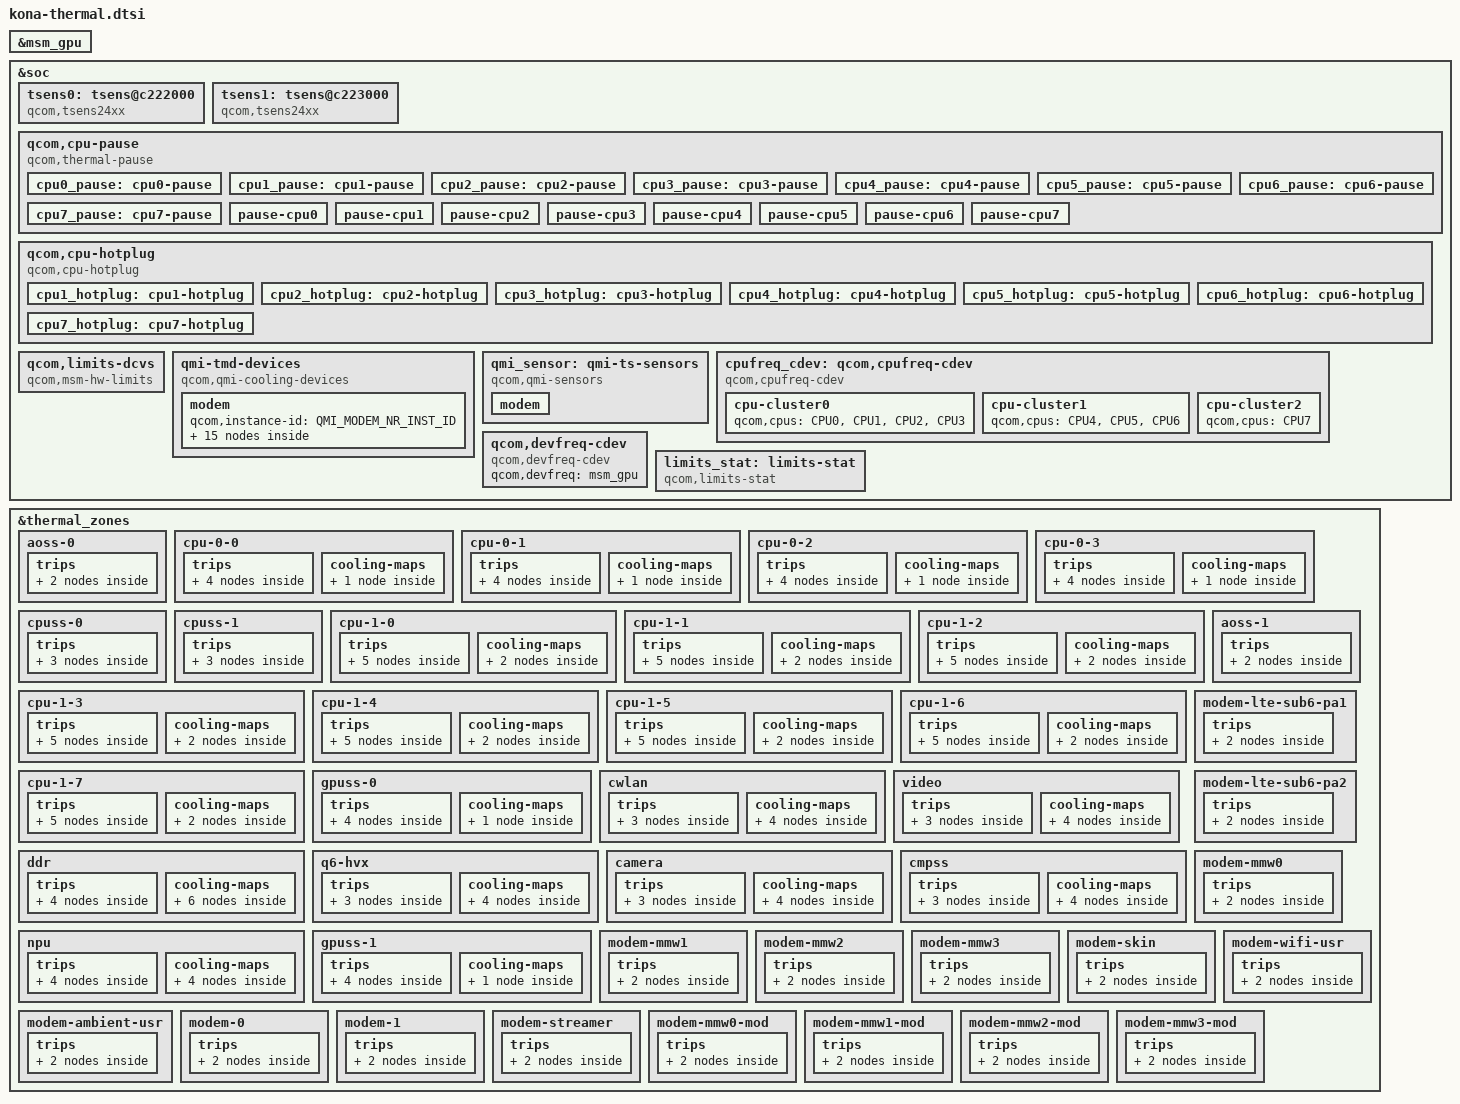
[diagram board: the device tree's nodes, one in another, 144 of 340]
#include <dt-bindings/thermal/thermal_qti.h>

&msm_gpu {
	#cooling-cells = <2>;
};

&soc {
	tsens0: tsens@c222000 {
		compatible = "qcom,tsens24xx";
		reg = <0xc222000 0x8>,
			<0xc263000 0x1ff>;
		reg-names = "tsens_srot_physical",
				"tsens_tm_physical";
		interrupts = <GIC_SPI 506 IRQ_TYPE_LEVEL_HIGH>,
				<GIC_SPI 508 IRQ_TYPE_LEVEL_HIGH>;
		interrupt-names = "tsens-upper-lower", "tsens-critical";
		tsens-reinit-wa;
		#thermal-sensor-cells = <1>;
	};

	tsens1: tsens@c223000 {
		compatible = "qcom,tsens24xx";
		reg = <0xc223000 0x8>,
			<0xc265000 0x1ff>;
		reg-names = "tsens_srot_physical",
			"tsens_tm_physical";
		interrupts = <GIC_SPI 507 IRQ_TYPE_LEVEL_HIGH>,
				<GIC_SPI 509 IRQ_TYPE_LEVEL_HIGH>;
		interrupt-names = "tsens-upper-lower", "tsens-critical";
		tsens-reinit-wa;
		#thermal-sensor-cells = <1>;
	};

	qcom,cpu-pause {
		compatible = "qcom,thermal-pause";

		cpu0_pause: cpu0-pause {
			qcom,cpus = <&CPU0>;
			qcom,cdev-alias = "thermal-pause-1";
			#cooling-cells = <2>;
		};

		cpu1_pause: cpu1-pause {
			qcom,cpus = <&CPU1>;
			qcom,cdev-alias = "thermal-pause-2";
			#cooling-cells = <2>;
		};

		cpu2_pause: cpu2-pause {
			qcom,cpus = <&CPU2>;
			qcom,cdev-alias = "thermal-pause-4";
			#cooling-cells = <2>;
		};

		cpu3_pause: cpu3-pause {
			qcom,cpus = <&CPU3>;
			qcom,cdev-alias = "thermal-pause-8";
			#cooling-cells = <2>;
		};

		cpu4_pause: cpu4-pause {
			qcom,cpus = <&CPU4>;
			qcom,cdev-alias = "thermal-pause-10";
			#cooling-cells = <2>;
		};

		cpu5_pause: cpu5-pause {
			qcom,cpus = <&CPU5>;
			qcom,cdev-alias = "thermal-pause-20";
			#cooling-cells = <2>;
		};

		cpu6_pause: cpu6-pause {
			qcom,cpus = <&CPU6>;
			qcom,cdev-alias = "thermal-pause-40";
			#cooling-cells = <2>;
		};

		cpu7_pause: cpu7-pause {
			qcom,cpus = <&CPU7>;
			qcom,cdev-alias = "thermal-pause-80";
			#cooling-cells = <2>;
		};

		/* Thermal-engine cooling devices */

		pause-cpu0 {
			qcom,cpus = <&CPU0>;
			qcom,cdev-alias = "pause-cpu0";
		};

		pause-cpu1 {
			qcom,cpus = <&CPU1>;
			qcom,cdev-alias = "pause-cpu1";
		};

		pause-cpu2 {
			qcom,cpus = <&CPU2>;
			qcom,cdev-alias = "pause-cpu2";
		};

		pause-cpu3 {
			qcom,cpus = <&CPU3>;
			qcom,cdev-alias = "pause-cpu3";
		};

		pause-cpu4 {
			qcom,cpus = <&CPU4>;
			qcom,cdev-alias = "pause-cpu4";
		};

		pause-cpu5 {
			qcom,cpus = <&CPU5>;
			qcom,cdev-alias = "pause-cpu5";
		};

		pause-cpu6 {
			qcom,cpus = <&CPU6>;
			qcom,cdev-alias = "pause-cpu6";
		};

		pause-cpu7 {
			qcom,cpus = <&CPU7>;
			qcom,cdev-alias = "pause-cpu7";
		};
	};

	qcom,cpu-hotplug {
		compatible = "qcom,cpu-hotplug";

		cpu1_hotplug: cpu1-hotplug {
			qcom,cpu = <&CPU1>;
			qcom,cdev-alias = "cpu-hotplug1";
			#cooling-cells = <2>;
		};

		cpu2_hotplug: cpu2-hotplug {
			qcom,cpu = <&CPU2>;
			qcom,cdev-alias = "cpu-hotplug2";
			#cooling-cells = <2>;
		};

		cpu3_hotplug: cpu3-hotplug {
			qcom,cpu = <&CPU3>;
			qcom,cdev-alias = "cpu-hotplug3";
			#cooling-cells = <2>;
		};

		cpu4_hotplug: cpu4-hotplug {
			qcom,cpu = <&CPU4>;
			qcom,cdev-alias = "cpu-hotplug4";
			#cooling-cells = <2>;
		};

		cpu5_hotplug: cpu5-hotplug {
			qcom,cpu = <&CPU5>;
			qcom,cdev-alias = "cpu-hotplug5";
			#cooling-cells = <2>;
		};

		cpu6_hotplug: cpu6-hotplug {
			qcom,cpu = <&CPU6>;
			qcom,cdev-alias = "cpu-hotplug6";
			#cooling-cells = <2>;
		};

		cpu7_hotplug: cpu7-hotplug {
			qcom,cpu = <&CPU7>;
			qcom,cdev-alias = "cpu-hotplug7";
			#cooling-cells = <2>;
		};
	};

	qcom,limits-dcvs {
		compatible = "qcom,msm-hw-limits";
		isens_vref_0p8-supply = <&pm8150_l5_ao>;
		isens-vref-0p8-settings = <880000 880000 20000>;
		isens_vref_1p8-supply = <&pm8150_l12_ao>;
		isens-vref-1p8-settings = <1800000 1800000 20000>;
	};

	qmi-tmd-devices {
		compatible = "qcom,qmi-cooling-devices";

		modem {
			qcom,instance-id = <QMI_MODEM_NR_INST_ID>;

			modem_pa: modem_pa {
				qcom,qmi-dev-name = "pa";
				#cooling-cells = <2>;
			};

			modem_pa_fr1: modem_pa_fr1 {
				qcom,qmi-dev-name = "pa_fr1";
				#cooling-cells = <2>;
			};

			modem_tj: modem_tj {
				qcom,qmi-dev-name = "modem";
				#cooling-cells = <2>;
			};

			modem_current: modem_current {
				qcom,qmi-dev-name = "modem_current";
				#cooling-cells = <2>;
			};

			modem_skin: modem_skin {
				qcom,qmi-dev-name = "modem_skin";
				#cooling-cells = <2>;
			};

			modem_mmw_skin0: modem_mmw_skin0 {
				qcom,qmi-dev-name = "mmw_skin0";
				#cooling-cells = <2>;
			};

			modem_mmw_skin1: modem_mmw_skin1 {
				qcom,qmi-dev-name = "mmw_skin1";
				#cooling-cells = <2>;
			};

			modem_mmw_skin2: modem_mmw_skin2 {
				qcom,qmi-dev-name = "mmw_skin2";
				#cooling-cells = <2>;
			};

			modem_mmw_skin3: modem_mmw_skin3 {
				qcom,qmi-dev-name = "mmw_skin3";
				#cooling-cells = <2>;
			};

			modem_mmw0: modem_mmw0 {
				qcom,qmi-dev-name = "mmw0";
				#cooling-cells = <2>;
			};

			modem_mmw1: modem_mmw1 {
				qcom,qmi-dev-name = "mmw1";
				#cooling-cells = <2>;
			};

			modem_mmw2: modem_mmw2 {
				qcom,qmi-dev-name = "mmw2";
				#cooling-cells = <2>;
			};

			modem_mmw3: modem_mmw3 {
				qcom,qmi-dev-name = "mmw3";
				#cooling-cells = <2>;
			};

			modem_bcl: modem_bcl {
				qcom,qmi-dev-name = "vbatt_low";
				#cooling-cells = <2>;
			};

			modem_charge_state: modem_charge_state {
				qcom,qmi-dev-name = "charge_state";
				#cooling-cells = <2>;
			};
		};
	};

	qmi_sensor: qmi-ts-sensors {
		compatible = "qcom,qmi-sensors";
		#thermal-sensor-cells = <1>;

		modem {
			qcom,instance-id = <QMI_MODEM_NR_INST_ID>;
			qcom,qmi-sensor-names = "pa",
						"pa_1",
						"qfe_wtr0",
						"modem_tsens",
						"qfe_mmw0",
						"qfe_mmw1",
						"qfe_mmw2",
						"qfe_mmw3",
						"xo_therm",
						"qfe_mmw_streamer0",
						"qfe_mmw0_mod",
						"qfe_mmw1_mod",
						"qfe_mmw2_mod",
						"qfe_mmw3_mod",
						"qfe_ret_pa0",
						"qfe_wtr_pa0",
						"qfe_wtr_pa1",
						"qfe_wtr_pa2",
						"qfe_wtr_pa3",
						"sys_therm1",
						"sys_therm2",
						"modem_tsens1";
		};
	};

	cpufreq_cdev: qcom,cpufreq-cdev {
		compatible = "qcom,cpufreq-cdev";
		cpu-cluster0 {
			qcom,cpus = <&CPU0 &CPU1 &CPU2 &CPU3>;
		};

		cpu-cluster1 {
			qcom,cpus = <&CPU4 &CPU5 &CPU6>;
		};

		cpu-cluster2 {
			qcom,cpus = <&CPU7>;
		};
	};

	qcom,devfreq-cdev {
		compatible = "qcom,devfreq-cdev";
		qcom,devfreq = <&msm_gpu>;
	};

	limits_stat: limits-stat {
		compatible = "qcom,limits-stat";
		qcom,limits-stat-sensor-names = "cpu-0-0",
						"cpu-0-1",
						"cpu-0-2",
						"cpu-0-3",
						"cpu-1-0",
						"cpu-1-1",
						"cpu-1-2",
						"cpu-1-3",
						"cpuss-0",
						"gpuss-0",
						"gpuss-1",
						"npu",
						"q6-hvx";
	};
};

&thermal_zones {
	aoss-0 {
		polling-delay-passive = <0>;
		polling-delay = <0>;
		thermal-sensors = <&tsens0 0>;
		trips {
			thermal-engine-config {
				temperature = <125000>;
				hysteresis = <1000>;
				type = "passive";
			};

			reset-mon-cfg {
				temperature = <115000>;
				hysteresis = <1000>;
				type = "passive";
			};
		};
	};

	cpu-0-0 {
		polling-delay-passive = <0>;
		polling-delay = <0>;
		thermal-sensors = <&tsens0 1>;
		trips {
			thermal-engine-config {
				temperature = <125000>;
				hysteresis = <1000>;
				type = "passive";
			};

			thermal-hal-config {
				temperature = <125000>;
				hysteresis = <1000>;
				type = "passive";
			};

			cpu00_config: cpu00-config {
				temperature = <110000>;
				hysteresis = <10000>;
				type = "passive";
			};

			reset-mon-cfg {
				temperature = <115000>;
				hysteresis = <1000>;
				type = "passive";
			};
		};

		cooling-maps {
			cpu00_cdev {
				trip = <&cpu00_config>;
				cooling-device = <&cpu0_pause 1 1>;
			};
		};
	};

	cpu-0-1 {
		polling-delay-passive = <0>;
		polling-delay = <0>;
		thermal-sensors = <&tsens0 2>;
		trips {
			thermal-engine-config {
				temperature = <125000>;
				hysteresis = <1000>;
				type = "passive";
			};

			thermal-hal-config {
				temperature = <125000>;
				hysteresis = <1000>;
				type = "passive";
			};

			cpu01_config: cpu01-config {
				temperature = <110000>;
				hysteresis = <10000>;
				type = "passive";
			};

			reset-mon-cfg {
				temperature = <115000>;
				hysteresis = <1000>;
				type = "passive";
			};
		};

		cooling-maps {
			cpu01_cdev {
				trip = <&cpu01_config>;
				cooling-device = <&cpu1_pause 1 1>;
			};
		};
	};

	cpu-0-2 {
		polling-delay-passive = <0>;
		polling-delay = <0>;
		thermal-sensors = <&tsens0 3>;
		trips {
			thermal-engine-config {
				temperature = <125000>;
				hysteresis = <1000>;
				type = "passive";
			};

			thermal-hal-config {
				temperature = <125000>;
				hysteresis = <1000>;
				type = "passive";
			};

			cpu02_config: cpu02-config {
				temperature = <110000>;
				hysteresis = <10000>;
				type = "passive";
			};

			reset-mon-cfg {
				temperature = <115000>;
				hysteresis = <1000>;
				type = "passive";
			};
		};

		cooling-maps {
			cpu02_cdev {
				trip = <&cpu02_config>;
				cooling-device = <&cpu2_pause 1 1>;
			};
		};
	};

	cpu-0-3 {
		polling-delay-passive = <0>;
		polling-delay = <0>;
		thermal-sensors = <&tsens0 4>;
		trips {
			thermal-engine-config {
				temperature = <125000>;
				hysteresis = <1000>;
				type = "passive";
			};

			thermal-hal-config {
				temperature = <125000>;
				hysteresis = <1000>;
				type = "passive";
			};

			cpu03_config: cpu03-config {
				temperature = <110000>;
				hysteresis = <10000>;
				type = "passive";
			};

			reset-mon-cfg {
				temperature = <115000>;
				hysteresis = <1000>;
				type = "passive";
			};
		};

		cooling-maps {
			cpu03_cdev {
				trip = <&cpu03_config>;
				cooling-device = <&cpu3_pause 1 1>;
			};
		};
	};

	cpuss-0 {
		polling-delay-passive = <0>;
		polling-delay = <0>;
		thermal-sensors = <&tsens0 5>;
		trips {
			thermal-engine-config {
				temperature = <125000>;
				hysteresis = <1000>;
				type = "passive";
			};

			thermal-hal-config {
				temperature = <125000>;
				hysteresis = <1000>;
				type = "passive";
			};

			reset-mon-cfg {
				temperature = <115000>;
				hysteresis = <1000>;
				type = "passive";
			};
		};
	};

	cpuss-1 {
		polling-delay-passive = <0>;
		polling-delay = <0>;
		thermal-sensors = <&tsens0 6>;
		trips {
			thermal-engine-config {
				temperature = <125000>;
				hysteresis = <1000>;
				type = "passive";
			};

			thermal-hal-config {
				temperature = <125000>;
				hysteresis = <1000>;
				type = "passive";
			};

			reset-mon-cfg {
				temperature = <115000>;
				hysteresis = <1000>;
				type = "passive";
			};
		};
	};

	cpu-1-0 {
		polling-delay-passive = <10>;
		polling-delay = <0>;
		thermal-sensors = <&tsens0 7>;
		trips {
			thermal-engine-config {
				temperature = <125000>;
				hysteresis = <1000>;
				type = "passive";
			};

			thermal-hal-config {
				temperature = <125000>;
				hysteresis = <1000>;
				type = "passive";
			};

			cpufreq_10_config: cpufreq-10-config {
				temperature = <75000>;
				hysteresis = <5000>;
				type = "passive";
			};

			cpu10_config: cpu10-config {
				temperature = <110000>;
				hysteresis = <10000>;
				type = "passive";
			};

			reset-mon-cfg {
				temperature = <115000>;
				hysteresis = <1000>;
				type = "passive";
			};
		};

		cooling-maps {
			cpufreq_cdev {
				trip = <&cpufreq_10_config>;
				cooling-device = <&cpu7_notify 1 1>;
			};

			cpu10_cdev {
				trip = <&cpu10_config>;
				cooling-device = <&cpu4_pause 1 1>;
			};
		};
	};

	cpu-1-1 {
		polling-delay-passive = <10>;
		polling-delay = <0>;
		thermal-sensors = <&tsens0 8>;
		trips {
			thermal-engine-config {
				temperature = <125000>;
				hysteresis = <1000>;
				type = "passive";
			};

			thermal-hal-config {
				temperature = <125000>;
				hysteresis = <1000>;
				type = "passive";
			};

			cpufreq_11_config: cpufreq-11-config {
				temperature = <75000>;
				hysteresis = <5000>;
				type = "passive";
			};

			cpu11_config: cpu11-config {
				temperature = <110000>;
				hysteresis = <10000>;
				type = "passive";
			};

			reset-mon-cfg {
				temperature = <115000>;
				hysteresis = <1000>;
				type = "passive";
			};
		};

		cooling-maps {
			cpufreq_cdev {
				trip = <&cpufreq_11_config>;
				cooling-device = <&cpu7_notify 1 1>;
			};

			cpu11_cdev {
				trip = <&cpu11_config>;
				cooling-device = <&cpu5_pause 1 1>;
			};
		};
	};

	cpu-1-2 {
		polling-delay-passive = <10>;
		polling-delay = <0>;
		thermal-sensors = <&tsens0 9>;
		trips {
			thermal-engine-config {
				temperature = <125000>;
				hysteresis = <1000>;
				type = "passive";
			};

			thermal-hal-config {
				temperature = <125000>;
				hysteresis = <1000>;
				type = "passive";
			};

			cpufreq_12_config: cpufreq-12-config {
				temperature = <75000>;
				hysteresis = <5000>;
				type = "passive";
			};

			cpu12_config: cpu12-config {
				temperature = <110000>;
				hysteresis = <10000>;
				type = "passive";
			};

			reset-mon-cfg {
				temperature = <115000>;
				hysteresis = <1000>;
				type = "passive";
			};
		};

		cooling-maps {
			cpufreq_cdev {
				trip = <&cpufreq_12_config>;
				cooling-device = <&cpu7_notify 1 1>;
			};

			cpu12_cdev {
				trip = <&cpu12_config>;
				cooling-device = <&cpu6_pause 1 1>;
			};
		};
	};

	cpu-1-3 {
		polling-delay-passive = <10>;
		polling-delay = <0>;
		thermal-sensors = <&tsens0 10>;
		trips {
			thermal-engine-config {
				temperature = <125000>;
				hysteresis = <1000>;
				type = "passive";
			};

			thermal-hal-config {
				temperature = <125000>;
				hysteresis = <1000>;
				type = "passive";
			};

			cpufreq_13_config: cpufreq-13-config {
				temperature = <75000>;
				hysteresis = <5000>;
				type = "passive";
			};

			cpu13_config: cpu13-config {
				temperature = <110000>;
				hysteresis = <10000>;
				type = "passive";
			};

			reset-mon-cfg {
				temperature = <115000>;
				hysteresis = <1000>;
				type = "passive";
			};
		};

		cooling-maps {
			cpufreq_cdev {
				trip = <&cpufreq_13_config>;
				cooling-device = <&cpu7_notify 1 1>;
			};

			cpu13_cdev {
				trip = <&cpu13_config>;
				cooling-device = <&cpu7_pause 1 1>;
			};
		};
	};

	cpu-1-4 {
		polling-delay-passive = <10>;
		polling-delay = <0>;
		thermal-sensors = <&tsens0 11>;
		trips {
			thermal-engine-config {
				temperature = <125000>;
				hysteresis = <1000>;
				type = "passive";
			};

			thermal-hal-config {
				temperature = <125000>;
				hysteresis = <1000>;
				type = "passive";
			};

			cpufreq_14_config: cpufreq-14-config {
				temperature = <75000>;
				hysteresis = <5000>;
				type = "passive";
			};

			cpu14_config: cpu14-config {
				temperature = <110000>;
				hysteresis = <10000>;
				type = "passive";
			};

			reset-mon-cfg {
				temperature = <115000>;
				hysteresis = <1000>;
				type = "passive";
			};
		};

		cooling-maps {
			cpufreq_cdev {
				trip = <&cpufreq_14_config>;
				cooling-device = <&cpu7_notify 1 1>;
			};

			cpu14_cdev {
				trip = <&cpu14_config>;
				cooling-device = <&cpu4_pause 1 1>;
			};
		};
	};

	cpu-1-5 {
		polling-delay-passive = <10>;
		polling-delay = <0>;
		thermal-sensors = <&tsens0 12>;
		trips {
			thermal-engine-config {
				temperature = <125000>;
				hysteresis = <1000>;
				type = "passive";
			};

			thermal-hal-config {
				temperature = <125000>;
				hysteresis = <1000>;
				type = "passive";
			};

			cpufreq_15_config: cpufreq-15-config {
				temperature = <75000>;
				hysteresis = <5000>;
				type = "passive";
			};

			cpu15_config: cpu15-config {
				temperature = <110000>;
				hysteresis = <10000>;
				type = "passive";
			};

			reset-mon-cfg {
				temperature = <115000>;
				hysteresis = <1000>;
				type = "passive";
			};
		};

		cooling-maps {
			cpufreq_cdev {
				trip = <&cpufreq_15_config>;
				cooling-device = <&cpu7_notify 1 1>;
			};

			cpu15_cdev {
				trip = <&cpu15_config>;
				cooling-device = <&cpu5_pause 1 1>;
			};
		};
	};

	cpu-1-6 {
		polling-delay-passive = <10>;
		polling-delay = <0>;
		thermal-sensors = <&tsens0 13>;
		trips {
			thermal-engine-config {
				temperature = <125000>;
				hysteresis = <1000>;
				type = "passive";
			};

			thermal-hal-config {
				temperature = <125000>;
				hysteresis = <1000>;
				type = "passive";
			};

			cpufreq_16_config: cpufreq-16-config {
				temperature = <75000>;
				hysteresis = <5000>;
				type = "passive";
			};

			cpu16_config: cpu16-config {
				temperature = <110000>;
				hysteresis = <10000>;
				type = "passive";
			};

			reset-mon-cfg {
				temperature = <115000>;
				hysteresis = <1000>;
				type = "passive";
			};
		};

		cooling-maps {
			cpufreq_cdev {
				trip = <&cpufreq_16_config>;
				cooling-device = <&cpu7_notify 1 1>;
			};

			cpu16_cdev {
				trip = <&cpu16_config>;
				cooling-device = <&cpu6_pause 1 1>;
			};
		};
	};

	cpu-1-7 {
		polling-delay-passive = <10>;
		polling-delay = <0>;
		thermal-sensors = <&tsens0 14>;
		trips {
			thermal-engine-config {
				temperature = <125000>;
				hysteresis = <1000>;
				type = "passive";
			};

			thermal-hal-config {
				temperature = <125000>;
				hysteresis = <1000>;
				type = "passive";
			};

			cpufreq_17_config: cpufreq-17-config {
				temperature = <75000>;
				hysteresis = <5000>;
				type = "passive";
			};

			cpu17_config: cpu17-config {
				temperature = <110000>;
				hysteresis = <10000>;
				type = "passive";
			};

			reset-mon-cfg {
				temperature = <115000>;
				hysteresis = <1000>;
				type = "passive";
			};
		};

		cooling-maps {
			cpufreq_cdev {
				trip = <&cpufreq_17_config>;
				cooling-device = <&cpu7_notify 1 1>;
			};

			cpu17_cdev {
				trip = <&cpu17_config>;
				cooling-device = <&cpu7_pause 1 1>;
			};
		};
	};

	gpuss-0 {
		polling-delay-passive = <10>;
		polling-delay = <0>;
		thermal-sensors = <&tsens0 15>;
		trips {
			thermal-engine-config {
				temperature = <125000>;
				hysteresis = <1000>;
				type = "passive";
			};

			thermal-hal-config {
				temperature = <125000>;
				hysteresis = <1000>;
				type = "passive";
			};

			gpuss0_trip0: gpuss0-trip0 {
				temperature = <95000>;
				hysteresis = <0>;
				type = "passive";
			};

			reset-mon-cfg {
				temperature = <115000>;
				hysteresis = <1000>;
				type = "passive";
			};
		};

		cooling-maps {
			gpu_cdev {
				trip = <&gpuss0_trip0>;
				cooling-device = <&msm_gpu THERMAL_NO_LIMIT
							THERMAL_NO_LIMIT>;
			};
		};
	};

	aoss-1 {
		polling-delay-passive = <0>;
		polling-delay = <0>;
		thermal-sensors = <&tsens1 0>;
		trips {
			thermal-engine-config {
				temperature = <125000>;
				hysteresis = <1000>;
				type = "passive";
			};

			reset-mon-cfg {
				temperature = <115000>;
				hysteresis = <1000>;
				type = "passive";
			};
		};
	};

	cwlan {
		polling-delay-passive = <10>;
		polling-delay = <0>;
		thermal-sensors = <&tsens1 1>;
		trips {
			thermal-engine-config {
				temperature = <125000>;
				hysteresis = <1000>;
				type = "passive";
			};

			cwlan_trip0: cwlan-trip0 {
				temperature = <100000>;
				hysteresis = <5000>;
				type = "passive";
			};

			reset-mon-cfg {
				temperature = <115000>;
				hysteresis = <1000>;
				type = "passive";
			};
		};

		cooling-maps {
			cdsp-cdev {
				trip = <&cwlan_trip0>;
				cooling-device = <&msm_cdsp_rm 3 3>;
			};

			gpu-cdev {
				trip = <&cwlan_trip0>;
				cooling-device = <&msm_gpu 1 1>;
			};

			modem-pa-cdev {
				trip = <&cwlan_trip0>;
				cooling-device = <&modem_pa 3 3>;
			};

			modem-tj-cdev {
				trip = <&cwlan_trip0>;
				cooling-device = <&modem_tj 3 3>;
			};
		};
	};

	video {
		polling-delay-passive = <10>;
		polling-delay = <0>;
		thermal-sensors = <&tsens1 2>;
		trips {
			thermal-engine-config {
				temperature = <125000>;
				hysteresis = <1000>;
				type = "passive";
			};

			video_trip0: video-trip0 {
				temperature = <100000>;
				hysteresis = <5000>;
				type = "passive";
			};

			reset-mon-cfg {
				temperature = <115000>;
				hysteresis = <1000>;
				type = "passive";
			};
		};

		cooling-maps {
			cdsp-cdev {
				trip = <&video_trip0>;
				cooling-device = <&msm_cdsp_rm 3 3>;
			};

			gpu-cdev {
				trip = <&video_trip0>;
				cooling-device = <&msm_gpu 1 1>;
			};

			modem-pa-cdev {
				trip = <&video_trip0>;
				cooling-device = <&modem_pa 3 3>;
			};

			modem-tj-cdev {
				trip = <&video_trip0>;
				cooling-device = <&modem_tj 3 3>;
			};
		};
	};

	ddr {
		polling-delay-passive = <10>;
		polling-delay = <0>;
		thermal-sensors = <&tsens1 3>;
		trips {
			thermal-engine-config {
				temperature = <125000>;
				hysteresis = <1000>;
				type = "passive";
			};

			ddr_trip0: ddr-trip0 {
				temperature = <95000>;
				hysteresis = <5000>;
				type = "passive";
			};

			ddr_trip1: ddr-trip1 {
				temperature = <100000>;
				hysteresis = <5000>;
				type = "passive";
			};

			reset-mon-cfg {
				temperature = <115000>;
				hysteresis = <1000>;
				type = "passive";
			};
		};

		cooling-maps {
			cdsp-cdev {
				trip = <&ddr_trip0>;
				cooling-device = <&msm_cdsp_rm 3 3>;
			};

			gpu-cdev {
				trip = <&ddr_trip0>;
				cooling-device = <&msm_gpu 1 1>;
			};

			cpu_cdev4 {
				trip = <&ddr_trip0>;
				cooling-device = <&CPU4 THERMAL_NO_LIMIT
						THERMAL_NO_LIMIT>;
			};

			cpu_cdev7 {
				trip = <&ddr_trip0>;
				cooling-device = <&CPU7 THERMAL_NO_LIMIT
						THERMAL_NO_LIMIT>;
			};

			modem-pa-cdev {
				trip = <&ddr_trip1>;
				cooling-device = <&modem_pa 3 3>;
			};

			modem-tj-cdev {
				trip = <&ddr_trip1>;
				cooling-device = <&modem_tj 3 3>;
			};
		};
	};

	q6-hvx {
		polling-delay-passive = <10>;
		polling-delay = <0>;
		thermal-sensors = <&tsens1 4>;
		trips {
			thermal-engine-config {
				temperature = <125000>;
				hysteresis = <1000>;
				type = "passive";
			};

			q6_hvx_trip0: q6-hvx-trip0 {
				temperature = <100000>;
				hysteresis = <5000>;
				type = "passive";
			};

			reset-mon-cfg {
				temperature = <115000>;
				hysteresis = <1000>;
				type = "passive";
			};
		};

		cooling-maps {
			cdsp-cdev {
				trip = <&q6_hvx_trip0>;
				cooling-device = <&msm_cdsp_rm 3 3>;
			};

			gpu-cdev {
				trip = <&q6_hvx_trip0>;
				cooling-device = <&msm_gpu 1 1>;
			};

			modem-pa-cdev {
				trip = <&q6_hvx_trip0>;
				cooling-device = <&modem_pa 3 3>;
			};

			modem-tj-cdev {
				trip = <&q6_hvx_trip0>;
				cooling-device = <&modem_tj 3 3>;
			};
		};
	};

	camera {
		polling-delay-passive = <10>;
		polling-delay = <0>;
		thermal-sensors = <&tsens1 5>;
		trips {
			thermal-engine-config {
				temperature = <125000>;
				hysteresis = <1000>;
				type = "passive";
			};

			camera_trip0: camera-trip0 {
				temperature = <100000>;
				hysteresis = <5000>;
				type = "passive";
			};

			reset-mon-cfg {
				temperature = <115000>;
				hysteresis = <1000>;
				type = "passive";
			};
		};

		cooling-maps {
			cdsp-cdev {
				trip = <&camera_trip0>;
				cooling-device = <&msm_cdsp_rm 3 3>;
			};

			gpu-cdev {
				trip = <&camera_trip0>;
				cooling-device = <&msm_gpu 1 1>;
			};

			modem-pa-cdev {
				trip = <&camera_trip0>;
				cooling-device = <&modem_pa 3 3>;
			};

			modem-tj-cdev {
				trip = <&camera_trip0>;
				cooling-device = <&modem_tj 3 3>;
			};
		};
	};

	cmpss {
		polling-delay-passive = <10>;
		polling-delay = <0>;
		thermal-sensors = <&tsens1 6>;
		trips {
			thermal-engine-config {
				temperature = <125000>;
				hysteresis = <1000>;
				type = "passive";
			};

			cmpss_trip0: cmpss-trip0 {
				temperature = <100000>;
				hysteresis = <5000>;
				type = "passive";
			};

			reset-mon-cfg {
				temperature = <115000>;
				hysteresis = <1000>;
				type = "passive";
			};
		};

		cooling-maps {
			cdsp-cdev {
				trip = <&cmpss_trip0>;
				cooling-device = <&msm_cdsp_rm 3 3>;
			};

			gpu-cdev {
				trip = <&cmpss_trip0>;
				cooling-device = <&msm_gpu 1 1>;
			};

			modem-pa-cdev {
				trip = <&cmpss_trip0>;
				cooling-device = <&modem_pa 3 3>;
			};

			modem-tj-cdev {
				trip = <&cmpss_trip0>;
				cooling-device = <&modem_tj 3 3>;
			};
		};
	};

	npu {
		polling-delay-passive = <10>;
		polling-delay = <0>;
		thermal-sensors = <&tsens1 7>;
		trips {
			thermal-engine-config {
				temperature = <125000>;
				hysteresis = <1000>;
				type = "passive";
			};

			thermal-hal-config {
				temperature = <125000>;
				hysteresis = <1000>;
				type = "passive";
			};

			npu_trip0: npu-trip0 {
				temperature = <100000>;
				hysteresis = <5000>;
				type = "passive";
			};

			reset-mon-cfg {
				temperature = <115000>;
				hysteresis = <1000>;
				type = "passive";
			};
		};

		cooling-maps {
			cdsp-cdev {
				trip = <&npu_trip0>;
				cooling-device = <&msm_cdsp_rm 3 3>;
			};

			gpu-cdev {
				trip = <&npu_trip0>;
				cooling-device = <&msm_gpu 1 1>;
			};

			modem-pa-cdev {
				trip = <&npu_trip0>;
				cooling-device = <&modem_pa 3 3>;
			};

			modem-tj-cdev {
				trip = <&npu_trip0>;
				cooling-device = <&modem_tj 3 3>;
			};
		};
	};

	gpuss-1 {
		polling-delay-passive = <10>;
		polling-delay = <0>;
		thermal-sensors = <&tsens1 8>;
		trips {
			thermal-engine-config {
				temperature = <125000>;
				hysteresis = <1000>;
				type = "passive";
			};

			thermal-hal-config {
				temperature = <125000>;
				hysteresis = <1000>;
				type = "passive";
			};

			gpuss1_trip0: gpuss1-trip0 {
				temperature = <95000>;
				hysteresis = <0>;
				type = "passive";
			};

			reset-mon-cfg {
				temperature = <115000>;
				hysteresis = <1000>;
				type = "passive";
			};
		};

		cooling-maps {
			gpu_cdev {
				trip = <&gpuss1_trip0>;
				cooling-device = <&msm_gpu THERMAL_NO_LIMIT
							THERMAL_NO_LIMIT>;
			};
		};
	};

	modem-lte-sub6-pa1 {
		polling-delay-passive = <0>;
		polling-delay = <0>;
		thermal-sensors = <&qmi_sensor
				(QMI_MODEM_NR_INST_ID+QMI_PA)>;
		trips {
			thermal-engine-config {
				temperature = <125000>;
				hysteresis = <1000>;
				type = "passive";
			};

			reset-mon-cfg {
				temperature = <115000>;
				hysteresis = <5000>;
				type = "passive";
			};
		};
	};

	modem-lte-sub6-pa2 {
		polling-delay-passive = <0>;
		polling-delay = <0>;
		thermal-sensors = <&qmi_sensor
				(QMI_MODEM_NR_INST_ID+QMI_PA_1)>;
		trips {
			thermal-engine-config {
				temperature = <125000>;
				hysteresis = <1000>;
				type = "passive";
			};

			reset-mon-cfg {
				temperature = <115000>;
				hysteresis = <5000>;
				type = "passive";
			};
		};
	};

	modem-mmw0 {
		polling-delay-passive = <0>;
		polling-delay = <0>;
		thermal-sensors = <&qmi_sensor
				(QMI_MODEM_NR_INST_ID+QMI_QFE_MMW_0)>;
		trips {
			thermal-engine-config {
				temperature = <125000>;
				hysteresis = <1000>;
				type = "passive";
			};

			reset-mon-cfg {
				temperature = <115000>;
				hysteresis = <5000>;
				type = "passive";
			};
		};
	};

	modem-mmw1 {
		polling-delay-passive = <0>;
		polling-delay = <0>;
		thermal-sensors = <&qmi_sensor
				(QMI_MODEM_NR_INST_ID+QMI_QFE_MMW_1)>;
		trips {
			thermal-engine-config {
				temperature = <125000>;
				hysteresis = <1000>;
				type = "passive";
			};

			reset-mon-cfg {
				temperature = <115000>;
				hysteresis = <5000>;
				type = "passive";
			};
		};
	};

	modem-mmw2 {
		polling-delay-passive = <0>;
		polling-delay = <0>;
		thermal-sensors = <&qmi_sensor
				(QMI_MODEM_NR_INST_ID+QMI_QFE_MMW_2)>;
		trips {
			thermal-engine-config {
				temperature = <125000>;
				hysteresis = <1000>;
				type = "passive";
			};

			reset-mon-cfg {
				temperature = <115000>;
				hysteresis = <5000>;
				type = "passive";
			};
		};
	};

	modem-mmw3 {
		polling-delay-passive = <0>;
		polling-delay = <0>;
		thermal-sensors = <&qmi_sensor
				(QMI_MODEM_NR_INST_ID+QMI_QFE_MMW_3)>;
		trips {
			thermal-engine-config {
				temperature = <125000>;
				hysteresis = <1000>;
				type = "passive";
			};

			reset-mon-cfg {
				temperature = <115000>;
				hysteresis = <5000>;
				type = "passive";
			};
		};
	};

	modem-skin {
		polling-delay-passive = <0>;
		polling-delay = <0>;
		thermal-sensors = <&qmi_sensor
				(QMI_MODEM_NR_INST_ID+QMI_XO_THERM)>;
		trips {
			thermal-engine-config {
				temperature = <125000>;
				hysteresis = <1000>;
				type = "passive";
			};

			reset-mon-cfg {
				temperature = <115000>;
				hysteresis = <5000>;
				type = "passive";
			};
		};
	};

	modem-wifi-usr {
		polling-delay-passive = <0>;
		polling-delay = <0>;
		thermal-sensors = <&qmi_sensor
				(QMI_MODEM_NR_INST_ID+QMI_SYS_THERM_1)>;
		trips {
			thermal-engine-config {
				temperature = <125000>;
				hysteresis = <1000>;
				type = "passive";
			};

			reset-mon-cfg {
				temperature = <115000>;
				hysteresis = <5000>;
				type = "passive";
			};
		};
	};

	modem-ambient-usr {
		polling-delay-passive = <0>;
		polling-delay = <0>;
		thermal-sensors = <&qmi_sensor
				(QMI_MODEM_NR_INST_ID+QMI_SYS_THERM_2)>;
		trips {
			thermal-engine-config {
				temperature = <125000>;
				hysteresis = <1000>;
				type = "passive";
			};

			reset-mon-cfg {
				temperature = <115000>;
				hysteresis = <5000>;
				type = "passive";
			};
		};
	};

	modem-0 {
		polling-delay-passive = <0>;
		polling-delay = <0>;
		thermal-sensors = <&qmi_sensor
				(QMI_MODEM_NR_INST_ID+QMI_MODEM_TSENS)>;
		trips {
			thermal-engine-config {
				temperature = <125000>;
				hysteresis = <1000>;
				type = "passive";
			};

			reset-mon-cfg {
				temperature = <115000>;
				hysteresis = <5000>;
				type = "passive";
			};
		};
	};

	modem-1 {
		polling-delay-passive = <0>;
		polling-delay = <0>;
		thermal-sensors = <&qmi_sensor
				(QMI_MODEM_NR_INST_ID+QMI_MODEM_TSENS_1)>;
		trips {
			thermal-engine-config {
				temperature = <125000>;
				hysteresis = <1000>;
				type = "passive";
			};

			reset-mon-cfg {
				temperature = <115000>;
				hysteresis = <5000>;
				type = "passive";
			};
		};
	};

	modem-streamer {
		polling-delay-passive = <0>;
		polling-delay = <0>;
		thermal-sensors = <&qmi_sensor
				(QMI_MODEM_NR_INST_ID+QMI_QFE_MMW_STREAMER_0)>;
		trips {
			thermal-engine-config {
				temperature = <125000>;
				hysteresis = <1000>;
				type = "passive";
			};

			reset-mon-cfg {
				temperature = <115000>;
				hysteresis = <5000>;
				type = "passive";
			};
		};
	};

	modem-mmw0-mod {
		polling-delay-passive = <0>;
		polling-delay = <0>;
		thermal-sensors = <&qmi_sensor
				(QMI_MODEM_NR_INST_ID+QMI_QFE_MMW_0_MOD)>;
		trips {
			thermal-engine-config {
				temperature = <125000>;
				hysteresis = <1000>;
				type = "passive";
			};

			reset-mon-cfg {
				temperature = <115000>;
				hysteresis = <5000>;
				type = "passive";
			};
		};
	};

	modem-mmw1-mod {
		polling-delay-passive = <0>;
		polling-delay = <0>;
		thermal-sensors = <&qmi_sensor
				(QMI_MODEM_NR_INST_ID+QMI_QFE_MMW_1_MOD)>;
		trips {
			thermal-engine-config {
				temperature = <125000>;
				hysteresis = <1000>;
				type = "passive";
			};

			reset-mon-cfg {
				temperature = <115000>;
				hysteresis = <5000>;
				type = "passive";
			};
		};
	};

	modem-mmw2-mod {
		polling-delay-passive = <0>;
		polling-delay = <0>;
		thermal-sensors = <&qmi_sensor
				(QMI_MODEM_NR_INST_ID+QMI_QFE_MMW_2_MOD)>;
		trips {
			thermal-engine-config {
				temperature = <125000>;
				hysteresis = <1000>;
				type = "passive";
			};

			reset-mon-cfg {
				temperature = <115000>;
				hysteresis = <5000>;
				type = "passive";
			};
		};
	};

	modem-mmw3-mod {
		polling-delay-passive = <0>;
		polling-delay = <0>;
		thermal-sensors = <&qmi_sensor
				(QMI_MODEM_NR_INST_ID+QMI_QFE_MMW_3_MOD)>;
		trips {
			thermal-engine-config {
				temperature = <125000>;
				hysteresis = <1000>;
				type = "passive";
			};

			reset-mon-cfg {
				temperature = <115000>;
				hysteresis = <5000>;
				type = "passive";
			};
		};
	};
};
